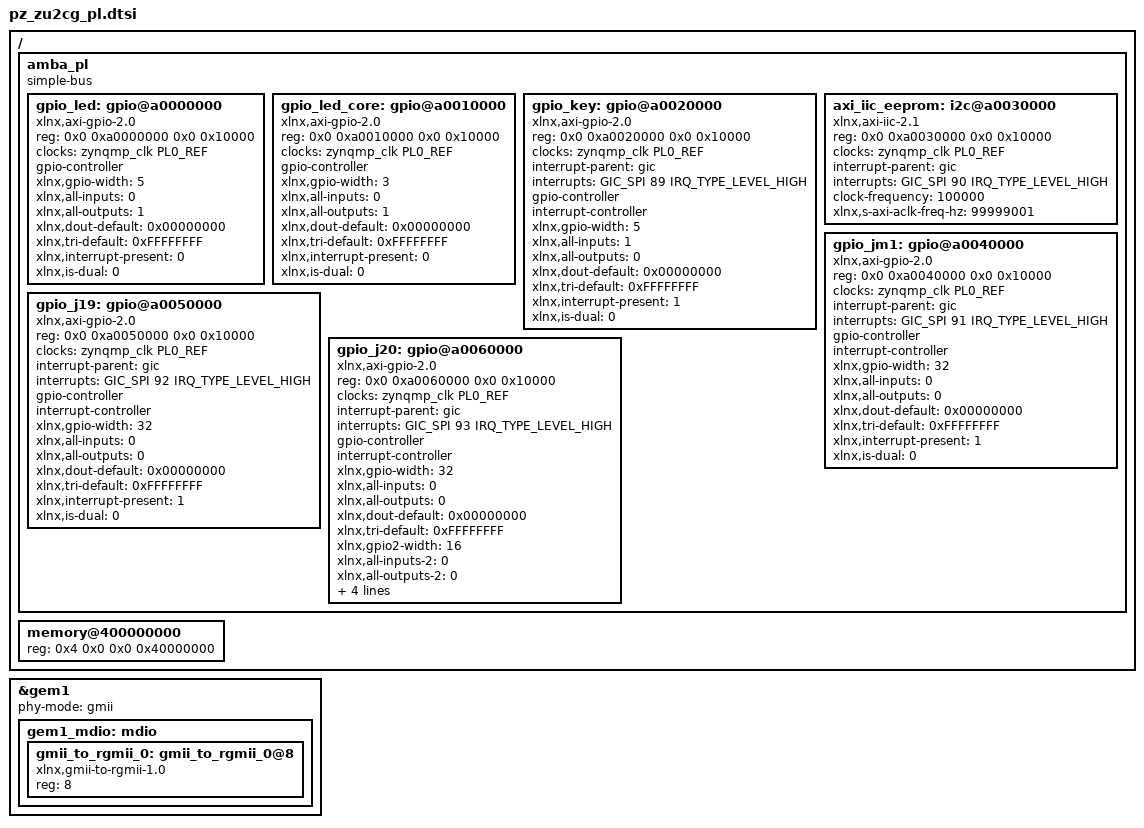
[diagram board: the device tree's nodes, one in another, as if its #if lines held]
// SPDX-License-Identifier: GPL-2.0
/*
 * PZ-ZU2CG Linux reference design: PL peripherals
 * Generated by tools/gen_pl_dts.py from projects/pz_zu2cg_linux/pz_zu2cg_linux.xsa
 * - do not edit; change the generator or the Vivado design and regenerate.
 */

#include <dt-bindings/clock/xlnx-zynqmp-clk.h>
#include <dt-bindings/interrupt-controller/arm-gic.h>
#include <dt-bindings/interrupt-controller/irq.h>

/ {
	amba_pl: amba_pl {
		compatible = "simple-bus";
		#address-cells = <2>;
		#size-cells = <2>;
		ranges;

		gpio_led: gpio@a0000000 {
			compatible = "xlnx,axi-gpio-2.0", "xlnx,xps-gpio-1.00.a";
			reg = <0x0 0xa0000000 0x0 0x10000>;
			clocks = <&zynqmp_clk PL0_REF>;
			gpio-controller;
			#gpio-cells = <2>;
			xlnx,gpio-width = <5>;
			xlnx,all-inputs = <0>;
			xlnx,all-outputs = <1>;
			xlnx,dout-default = <0x00000000>;
			xlnx,tri-default = <0xFFFFFFFF>;
			xlnx,interrupt-present = <0>;
			xlnx,is-dual = <0>;
		};

		gpio_led_core: gpio@a0010000 {
			compatible = "xlnx,axi-gpio-2.0", "xlnx,xps-gpio-1.00.a";
			reg = <0x0 0xa0010000 0x0 0x10000>;
			clocks = <&zynqmp_clk PL0_REF>;
			gpio-controller;
			#gpio-cells = <2>;
			xlnx,gpio-width = <3>;
			xlnx,all-inputs = <0>;
			xlnx,all-outputs = <1>;
			xlnx,dout-default = <0x00000000>;
			xlnx,tri-default = <0xFFFFFFFF>;
			xlnx,interrupt-present = <0>;
			xlnx,is-dual = <0>;
		};

		gpio_key: gpio@a0020000 {
			compatible = "xlnx,axi-gpio-2.0", "xlnx,xps-gpio-1.00.a";
			reg = <0x0 0xa0020000 0x0 0x10000>;
			clocks = <&zynqmp_clk PL0_REF>;
			interrupt-parent = <&gic>;
			interrupts = <GIC_SPI 89 IRQ_TYPE_LEVEL_HIGH>;
			gpio-controller;
			#gpio-cells = <2>;
			interrupt-controller;
			#interrupt-cells = <2>;
			#address-cells = <0>;
			xlnx,gpio-width = <5>;
			xlnx,all-inputs = <1>;
			xlnx,all-outputs = <0>;
			xlnx,dout-default = <0x00000000>;
			xlnx,tri-default = <0xFFFFFFFF>;
			xlnx,interrupt-present = <1>;
			xlnx,is-dual = <0>;
		};

		axi_iic_eeprom: i2c@a0030000 {
			compatible = "xlnx,axi-iic-2.1", "xlnx,xps-iic-2.00.a";
			reg = <0x0 0xa0030000 0x0 0x10000>;
			clocks = <&zynqmp_clk PL0_REF>;
			interrupt-parent = <&gic>;
			interrupts = <GIC_SPI 90 IRQ_TYPE_LEVEL_HIGH>;
			#address-cells = <1>;
			#size-cells = <0>;
			clock-frequency = <100000>;
			xlnx,s-axi-aclk-freq-hz = <99999001>;
		};

		gpio_jm1: gpio@a0040000 {
			compatible = "xlnx,axi-gpio-2.0", "xlnx,xps-gpio-1.00.a";
			reg = <0x0 0xa0040000 0x0 0x10000>;
			clocks = <&zynqmp_clk PL0_REF>;
			interrupt-parent = <&gic>;
			interrupts = <GIC_SPI 91 IRQ_TYPE_LEVEL_HIGH>;
			gpio-controller;
			#gpio-cells = <2>;
			interrupt-controller;
			#interrupt-cells = <2>;
			#address-cells = <0>;
			xlnx,gpio-width = <32>;
			xlnx,all-inputs = <0>;
			xlnx,all-outputs = <0>;
			xlnx,dout-default = <0x00000000>;
			xlnx,tri-default = <0xFFFFFFFF>;
			xlnx,interrupt-present = <1>;
			xlnx,is-dual = <0>;
		};

		gpio_j19: gpio@a0050000 {
			compatible = "xlnx,axi-gpio-2.0", "xlnx,xps-gpio-1.00.a";
			reg = <0x0 0xa0050000 0x0 0x10000>;
			clocks = <&zynqmp_clk PL0_REF>;
			interrupt-parent = <&gic>;
			interrupts = <GIC_SPI 92 IRQ_TYPE_LEVEL_HIGH>;
			gpio-controller;
			#gpio-cells = <2>;
			interrupt-controller;
			#interrupt-cells = <2>;
			#address-cells = <0>;
			xlnx,gpio-width = <32>;
			xlnx,all-inputs = <0>;
			xlnx,all-outputs = <0>;
			xlnx,dout-default = <0x00000000>;
			xlnx,tri-default = <0xFFFFFFFF>;
			xlnx,interrupt-present = <1>;
			xlnx,is-dual = <0>;
		};

		gpio_j20: gpio@a0060000 {
			compatible = "xlnx,axi-gpio-2.0", "xlnx,xps-gpio-1.00.a";
			reg = <0x0 0xa0060000 0x0 0x10000>;
			clocks = <&zynqmp_clk PL0_REF>;
			interrupt-parent = <&gic>;
			interrupts = <GIC_SPI 93 IRQ_TYPE_LEVEL_HIGH>;
			gpio-controller;
			#gpio-cells = <2>;
			interrupt-controller;
			#interrupt-cells = <2>;
			#address-cells = <0>;
			xlnx,gpio-width = <32>;
			xlnx,all-inputs = <0>;
			xlnx,all-outputs = <0>;
			xlnx,dout-default = <0x00000000>;
			xlnx,tri-default = <0xFFFFFFFF>;
			xlnx,gpio2-width = <16>;
			xlnx,all-inputs-2 = <0>;
			xlnx,all-outputs-2 = <0>;
			xlnx,dout-default-2 = <0x00000000>;
			xlnx,tri-default-2 = <0xFFFFFFFF>;
			xlnx,interrupt-present = <1>;
			xlnx,is-dual = <1>;
		};
	};

	/*
	 * PL DDR4 (ddr4_0, MT40A512M16TB-062E) behind M_AXI_HPM0_FPD,
	 * 1024 MB at 0x400000000, kept out of Linux's RAM for DMA buffers.
	 * pl_ddr4_dma is a coherent DMA pool: a DMA-capable node (e.g. an AXI DMA added to
	 * the PL) takes it with memory-region = <&pl_ddr4_dma>, and dma_alloc_coherent() for
	 * that device then allocates here (mapped uncached). PL logic can also use the MIG
	 * directly; /dev/mem reaches it too. Build with -DPL_DDR4_AS_RAM to make it system
	 * RAM instead. Either way the bitstream must be loaded before Linux starts (U-Boot
	 * does it from its preboot command).
	 */
#ifdef PL_DDR4_AS_RAM
	memory@400000000 {
		device_type = "memory";
		reg = <0x4 0x0 0x0 0x40000000>;
	};
#else
	reserved-memory {
		#address-cells = <2>;
		#size-cells = <2>;
		ranges;

		pl_ddr4_dma: pl-ddr4-dma@400000000 {
			compatible = "shared-dma-pool";
			reg = <0x4 0x0 0x0 0x40000000>;
			no-map;
		};
	};
#endif
};

/* PS GEM1 over EMIO into gmii_to_rgmii_0; its management registers sit on GEM1's MDIO bus. */
&gem1 {
	status = "okay";
	phy-mode = "gmii";
	gem1_mdio: mdio {
		#address-cells = <1>;
		#size-cells = <0>;
		gmii_to_rgmii_0: gmii_to_rgmii_0@8 {
			compatible = "xlnx,gmii-to-rgmii-1.0";
			reg = <8>;
		};
	};
};
